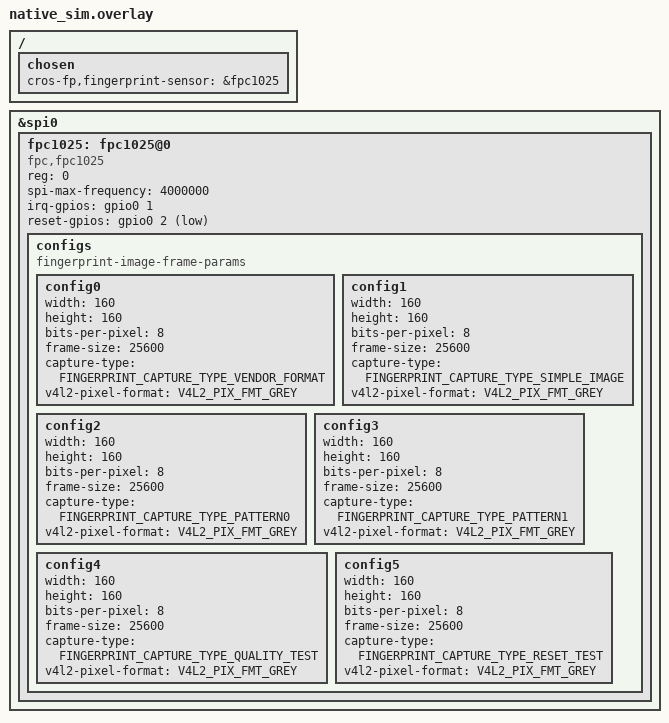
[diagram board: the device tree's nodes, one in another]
/* Copyright 2023 The ChromiumOS Authors
 * Use of this source code is governed by a BSD-style license that can be
 * found in the LICENSE file.
 */

/ {
	chosen {
		cros-fp,fingerprint-sensor = &fpc1025;
	};
};

&spi0 {
	fpc1025: fpc1025@0 {
		compatible = "fpc,fpc1025";
		reg = <0>;
		spi-max-frequency = <4000000>;

		configs {
			compatible = "fingerprint-image-frame-params";
			config0 {
				width = <160>;
				height = <160>;
				bits-per-pixel = <8>;
				frame-size = <25600>;
				capture-type = "FINGERPRINT_CAPTURE_TYPE_VENDOR_FORMAT";
				v4l2-pixel-format = "V4L2_PIX_FMT_GREY";
			};
			config1 {
				width = <160>;
				height = <160>;
				bits-per-pixel = <8>;
				frame-size = <25600>;
				capture-type = "FINGERPRINT_CAPTURE_TYPE_SIMPLE_IMAGE";
				v4l2-pixel-format = "V4L2_PIX_FMT_GREY";
			};
			config2 {
				width = <160>;
				height = <160>;
				bits-per-pixel = <8>;
				frame-size = <25600>;
				capture-type = "FINGERPRINT_CAPTURE_TYPE_PATTERN0";
				v4l2-pixel-format = "V4L2_PIX_FMT_GREY";
			};
			config3 {
				width = <160>;
				height = <160>;
				bits-per-pixel = <8>;
				frame-size = <25600>;
				capture-type = "FINGERPRINT_CAPTURE_TYPE_PATTERN1";
				v4l2-pixel-format = "V4L2_PIX_FMT_GREY";
			};
			config4 {
				width = <160>;
				height = <160>;
				bits-per-pixel = <8>;
				frame-size = <25600>;
				capture-type = "FINGERPRINT_CAPTURE_TYPE_QUALITY_TEST";
				v4l2-pixel-format = "V4L2_PIX_FMT_GREY";
			};
			config5 {
				width = <160>;
				height = <160>;
				bits-per-pixel = <8>;
				frame-size = <25600>;
				capture-type = "FINGERPRINT_CAPTURE_TYPE_RESET_TEST";
				v4l2-pixel-format = "V4L2_PIX_FMT_GREY";
			};
		};

		irq-gpios = <&gpio0 1 (GPIO_ACTIVE_HIGH | GPIO_PULL_DOWN)>;
		reset-gpios = <&gpio0 2 GPIO_ACTIVE_LOW>;
	};
};
